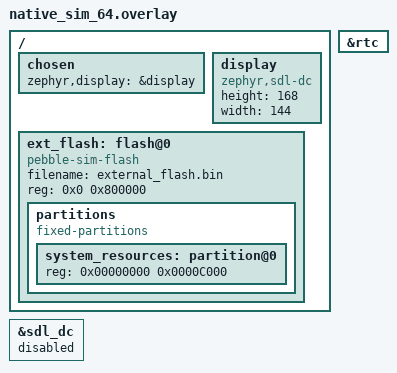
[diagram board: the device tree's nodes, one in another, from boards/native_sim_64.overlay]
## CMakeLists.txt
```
#-------------------------------------------------------------------------------
# PebbleOS CoreOS
#

cmake_minimum_required(VERSION 3.13.1)
find_package(Zephyr REQUIRED HINTS $ENV{ZEPHYR_BASE})

set(CMAKE_C_FLAGS "-Og")

project(CoreOS LANGUAGES C)

target_sources(app PRIVATE 
    src/main.c
)

add_subdirectory(src)
```

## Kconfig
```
# Copyright (c) 2021 Nordic Semiconductor ASA
# SPDX-License-Identifier: Apache-2.0
#
# This file is the application Kconfig entry point. All application Kconfig
# options can be defined here or included via other application Kconfig files.
# You can browse these options using the west targets menuconfig (terminal) or
# guiconfig (GUI).

menu "Zephyr"
    source "Kconfig.zephyr"

    choice
        prompt "Select target device"

        config DEVICE_TINTIN
            bool "Target TinTin Device"
        

        config DEVICE_BLANCA
            bool "Target Blanca Device"
    endchoice

endmenu

module = COREOS
module-str = COREOS

source "subsys/logging/Kconfig.template.log_config"
```

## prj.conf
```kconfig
# Display Configurations
CONFIG_DISPLAY=y

CONFIG_DEBUG_OPTIMIZATIONS=y

CONFIG_EVENTS=y

# RTC
#CONFIG_RTC=y
#CONFIG_RTC_UPDATE=y

# Flash
CONFIG_FLASH=y
CONFIG_FLASH_MAP=y

# CRC
CONFIG_CRC=y

# Logging
CONFIG_LOG=y
CONFIG_HEAP_MEM_POOL_SIZE=65536

# LVGL
CONFIG_LVGL=y
CONFIG_LV_CONF_MINIMAL=y
CONFIG_LV_USE_LOG=y
CONFIG_LV_LOG_LEVEL_TRACE=y
#CONFIG_LV_Z_FLUSH_THREAD=y
# CONFIG_LV_USE_LOG=y
CONFIG_LV_USE_LABEL=y
# CONFIG_LV_USE_ARC=y
# CONFIG_LV_USE_MONKEY=y
CONFIG_LV_COLOR_DEPTH_1=y
CONFIG_LV_Z_MEM_POOL_SIZE=16384
```

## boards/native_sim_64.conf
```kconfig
# Display Configs
CONFIG_SDL_DISPLAY=y
CONFIG_SDL_DISPLAY_DEFAULT_PIXEL_FORMAT_MONO10=y
CONFIG_SDL_DISPLAY_MONO_MSB_FIRST=n
CONFIG_SDL_DISPLAY_MONO_VTILED=n
CONFIG_SDL_DISPLAY_ZOOM_PCT=200

# Flash Sim
CONFIG_PEBBLE_SIM_FLASH=y
```

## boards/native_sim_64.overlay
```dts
/ {
    chosen {
        zephyr,display = &display;
    };

    display: display {
        compatible = "zephyr,sdl-dc";
        height = <168>;
        width = <144>;
    };

    ext_flash: flash@0 {
        compatible = "pebble-sim-flash";
        status = "okay";
        filename = "external_flash.bin";
        reg = < 0x0 0x800000 >;
		#address-cells = < 0x1 >;
		#size-cells = < 0x1 >;
	   
        partitions {
            compatible = "fixed-partitions";
            #address-cells = <1>;
            #size-cells = <1>;

            system_resources: partition@0 {
                reg = <0x00000000 0x0000C000>;
            };
        };

    };
};

&rtc {
    status = "okay";
};

&sdl_dc {
    status = "disabled";
};
```

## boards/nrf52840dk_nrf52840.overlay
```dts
/ {
	   
	
};

&mx25r64 {
	partitions {
  	compatible = "fixed-partitions";
    #address-cells = <1>;
    #size-cells = <1>;

    system_resources: partition@0 {
    	reg = <0x00000000 0x0000C000>;
    };
  };
};
```

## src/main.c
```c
/*
 * Copyright (C) Ovyl
 */

/**
 * @file main.c
 * @author Evan Stoddard
 * @brief
 */

#include <zephyr/kernel.h>

#include "kernel/main_thread.h"

#include "graphics/framebuffer.h"
#include "graphics/gcontext.h"
#include "ui/window.h"

#include "process_management/app_manager.h"

#include "apps/launcher/launcher_app.h"

#include "pebble_device.h"

/*****************************************************************************
 * Definitions
 *****************************************************************************/

/*****************************************************************************
 * Variables
 *****************************************************************************/

/*****************************************************************************
 * Private Functions
 *****************************************************************************/

Window window;

GContext context;
FrameBuffer fb;

/*****************************************************************************
 * Functions
 *****************************************************************************/

int main(void)
{

    GSize size = GSize(DEVICE_DISPLAY_WIDTH_PIXELS, DEVICE_DISPLAY_HEIGHT_PIXELS);

    framebuffer_init(&fb, &size);

    graphics_context_init(&context, &fb, GContextInitializationMode_App);

    /* launcher_app_main(); */

    /* window_render(launcher_app_window(), &context); */

    /* framebuffer_flush(&fb); */

    main_thread_init();

    static AppLaunchConfig launch_config = {0};
    launch_config.md = launcher_app_process_metadata();

    app_manager_start_app(&launch_config);

    return 0;
}
```

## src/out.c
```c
unsigned char outfile_bin[] = {
  0x00, 0x0c, 0x5d, 0x00, 0x00, 0x00, 0xff, 0x00, 0x00, 0x00, 0x00, 0x00,
  0x00, 0x00, 0x00, 0x00, 0x00, 0x00, 0x00, 0x00, 0x00, 0x00, 0x00, 0x00,
  0x00, 0x00, 0x00, 0x00, 0x00, 0x00, 0x00, 0x00, 0x00, 0x00, 0x00, 0x00,
  0x00, 0x00, 0x00, 0x00, 0x00, 0x00, 0x00, 0x00, 0x00, 0x00, 0x00, 0x00,
  0x00, 0x00, 0x00, 0x00, 0x00, 0x00, 0x00, 0x00, 0x00, 0x00, 0x00, 0x00,
  0x00, 0x00, 0x00, 0x00, 0x00, 0x00, 0x00, 0x00, 0x00, 0x00, 0x00, 0x00,
  0x00, 0x00, 0x00, 0x00, 0x00, 0x00, 0x00, 0x00, 0x00, 0x00, 0x00, 0x00,
  0x00, 0x00, 0x00, 0x00, 0x00, 0x00, 0x00, 0x00, 0x00, 0x00, 0x00, 0x00,
  0x00, 0x00, 0x00, 0x00, 0x00, 0x00, 0x00, 0x00, 0x00, 0x00, 0x00, 0x00,
  0x00, 0x00, 0x00, 0x00, 0x00, 0x00, 0x00, 0x00, 0x00, 0x00, 0x00, 0x00,
  0x00, 0x00, 0x00, 0x00, 0x00, 0x00, 0x00, 0x00, 0x00, 0x00, 0x00, 0x00,
  0x00, 0x00, 0x00, 0x00, 0x20, 0x01, 0x00, 0x00, 0x21, 0x01, 0x01, 0x00,
  0x22, 0x01, 0x02, 0x00, 0x23, 0x01, 0x03, 0x00, 0x24, 0x01, 0x04, 0x00,
  0x25, 0x01, 0x05, 0x00, 0x26, 0x01, 0x06, 0x00, 0x27, 0x01, 0x07, 0x00,
  0x28, 0x01, 0x08, 0x00, 0x29, 0x01, 0x09, 0x00, 0x2a, 0x01, 0x0a, 0x00,
  0x2b, 0x01, 0x0b, 0x00, 0x2c, 0x01, 0x0c, 0x00, 0x2d, 0x01, 0x0d, 0x00,
  0x2e, 0x01, 0x0e, 0x00, 0x2f, 0x01, 0x0f, 0x00, 0x30, 0x01, 0x10, 0x00,
  0x31, 0x01, 0x11, 0x00, 0x32, 0x01, 0x12, 0x00, 0x33, 0x01, 0x13, 0x00,
  0x34, 0x01, 0x14, 0x00, 0x35, 0x01, 0x15, 0x00, 0x36, 0x01, 0x16, 0x00,
  0x37, 0x01, 0x17, 0x00, 0x38, 0x01, 0x18, 0x00, 0x39, 0x01, 0x19, 0x00,
  0x3a, 0x01, 0x1a, 0x00, 0x3b, 0x01, 0x1b, 0x00, 0x3c, 0x01, 0x1c, 0x00,
  0x3d, 0x01, 0x1d, 0x00, 0x3e, 0x01, 0x1e, 0x00, 0x3f, 0x01, 0x1f, 0x00,
  0x40, 0x01, 0x20, 0x00, 0x41, 0x01, 0x21, 0x00, 0x42, 0x01, 0x22, 0x00,
  0x43, 0x01, 0x23, 0x00, 0x44, 0x01, 0x24, 0x00, 0x45, 0x01, 0x25, 0x00,
  0x46, 0x01, 0x26, 0x00, 0x47, 0x01, 0x27, 0x00, 0x48, 0x01, 0x28, 0x00,
  0x49, 0x01, 0x29, 0x00, 0x4a, 0x01, 0x2a, 0x00, 0x4b, 0x01, 0x2b, 0x00,
  0x4c, 0x01, 0x2c, 0x00, 0x4d, 0x01, 0x2d, 0x00, 0x4e, 0x01, 0x2e, 0x00,
  0x4f, 0x01, 0x2f, 0x00, 0x50, 0x01, 0x30, 0x00, 0x51, 0x01, 0x31, 0x00,
  0x52, 0x01, 0x32, 0x00, 0x53, 0x01, 0x33, 0x00, 0x54, 0x01, 0x34, 0x00,
  0x55, 0x01, 0x35, 0x00, 0x56, 0x01, 0x36, 0x00, 0x57, 0x01, 0x37, 0x00,
  0x58, 0x01, 0x38, 0x00, 0x59, 0x01, 0x39, 0x00, 0x5a, 0x01, 0x3a, 0x00,
  0x00, 0x00, 0x00, 0x00, 0x5c, 0x01, 0x3b, 0x00, 0x00, 0x00, 0x00, 0x00,
  0x5e, 0x01, 0x3c, 0x00, 0x5f, 0x01, 0x3d, 0x00, 0x60, 0x02, 0x3e, 0x00,
  0x61, 0x01, 0x40, 0x00, 0x62, 0x01, 0x41, 0x00, 0x63, 0x01, 0x42, 0x00,
  0x64, 0x01, 0x43, 0x00, 0x65, 0x01, 0x44, 0x00, 0x66, 0x01, 0x45, 0x00,
  0x67, 0x01, 0x46, 0x00, 0x68, 0x01, 0x47, 0x00, 0x69, 0x01, 0x48, 0x00,
  0x6a, 0x01, 0x49, 0x00, 0x6b, 0x01, 0x4a, 0x00, 0x6c, 0x01, 0x4b, 0x00,
  0x6d, 0x01, 0x4c, 0x00, 0x6e, 0x01, 0x4d, 0x00, 0x6f, 0x01, 0x4e, 0x00,
  0x70, 0x01, 0x4f, 0x00, 0x71, 0x01, 0x50, 0x00, 0x72, 0x01, 0x51, 0x00,
  0x73, 0x01, 0x52, 0x00, 0x74, 0x01, 0x53, 0x00, 0x75, 0x01, 0x54, 0x00,
  0x76, 0x01, 0x55, 0x00, 0x77, 0x01, 0x56, 0x00, 0x78, 0x01, 0x57, 0x00,
  0x79, 0x01, 0x58, 0x00, 0x7a, 0x01, 0x59, 0x00, 0x00, 0x00, 0x00, 0x00,
  0x7c, 0x01, 0x5a, 0x00, 0x00, 0x00, 0x00, 0x00, 0x7e, 0x02, 0x5b, 0x00,
  0x00, 0x00, 0x00, 0x00, 0x00, 0x00, 0x00, 0x00, 0x00, 0x00, 0x00, 0x00,
  0x00, 0x00, 0x00, 0x00, 0x00, 0x00, 0x00, 0x00, 0x00, 0x00, 0x00, 0x00,
  0x00, 0x00, 0x00, 0x00, 0x00, 0x00, 0x00, 0x00, 0x00, 0x00, 0x00, 0x00,
  0x00, 0x00, 0x00, 0x00, 0x00, 0x00, 0x00, 0x00, 0x00, 0x00, 0x00, 0x00,
  0x00, 0x00, 0x00, 0x00, 0x00, 0x00, 0x00, 0x00, 0x00, 0x00, 0x00, 0x00,
  0x00, 0x00, 0x00, 0x00, 0x00, 0x00, 0x00, 0x00, 0x00, 0x00, 0x00, 0x00,
  0x00, 0x00, 0x00, 0x00, 0x00, 0x00, 0x00, 0x00, 0x00, 0x00, 0x00, 0x00,
  0x00, 0x00, 0x00, 0x00, 0x00, 0x00, 0x00, 0x00, 0x00, 0x00, 0x00, 0x00,
  0x00, 0x00, 0x00, 0x00, 0x00, 0x00, 0x00, 0x00, 0x00, 0x00, 0x00, 0x00,
  0x00, 0x00, 0x00, 0x00, 0x00, 0x00, 0x00, 0x00, 0x00, 0x00, 0x00, 0x00,
  0x00, 0x00, 0x00, 0x00, 0x00, 0x00, 0x00, 0x00, 0x00, 0x00, 0x00, 0x00,
  0x00, 0x00, 0x00, 0x00, 0x00, 0x00, 0x00, 0x00, 0x00, 0x00, 0x00, 0x00,
  0x00, 0x00, 0x00, 0x00, 0x00, 0x00, 0x00, 0x00, 0x00, 0x00, 0x00, 0x00,
  0x00, 0x00, 0x00, 0x00, 0x00, 0x00, 0x00, 0x00, 0x00, 0x00, 0x00, 0x00,
  0x00, 0x00, 0x00, 0x00, 0x00, 0x00, 0x00, 0x00, 0x00, 0x00, 0x00, 0x00,
  0x00, 0x00, 0x00, 0x00, 0x00, 0x00, 0x00, 0x00, 0x00, 0x00, 0x00, 0x00,
  0x00, 0x00, 0x00, 0x00, 0x00, 0x00, 0x00, 0x00, 0x00, 0x00, 0x00, 0x00,
  0x00, 0x00, 0x00, 0x00, 0x00, 0x00, 0x00, 0x00, 0x00, 0x00, 0x00, 0x00,
  0x00, 0x00, 0x00, 0x00, 0x00, 0x00, 0x00, 0x00, 0x00, 0x00, 0x00, 0x00,
  0x00, 0x00, 0x00, 0x00, 0x00, 0x00, 0x00, 0x00, 0x00, 0x00, 0x00, 0x00,
  0x00, 0x00, 0x00, 0x00, 0x00, 0x00, 0x00, 0x00, 0x00, 0x00, 0x00, 0x00,
  0x00, 0x00, 0x00, 0x00, 0x00, 0x00, 0x00, 0x00, 0x00, 0x00, 0x00, 0x00,
  0x00, 0x00, 0x00, 0x00, 0x00, 0x00, 0x00, 0x00, 0x00, 0x00, 0x00, 0x00,
  0x00, 0x00, 0x00, 0x00, 0x00, 0x00, 0x00, 0x00, 0x00, 0x00, 0x00, 0x00,
  0x00, 0x00, 0x00, 0x00, 0x00, 0x00, 0x00, 0x00, 0x00, 0x00, 0x00, 0x00,
  0x00, 0x00, 0x00, 0x00, 0x00, 0x00, 0x00, 0x00, 0x00, 0x00, 0x00, 0x00,
  0x00, 0x00, 0x00, 0x00, 0x00, 0x00, 0x00, 0x00, 0x00, 0x00, 0x00, 0x00,
  0x00, 0x00, 0x00, 0x00, 0x00, 0x00, 0x00, 0x00, 0x00, 0x00, 0x00, 0x00,
  0x00, 0x00, 0x00, 0x00, 0x00, 0x00, 0x00, 0x00, 0x00, 0x00, 0x00, 0x00,
  0x00, 0x00, 0x00, 0x00, 0x00, 0x00, 0x00, 0x00, 0x00, 0x00, 0x00, 0x00,
  0x00, 0x00, 0x00, 0x00, 0x00, 0x00, 0x00, 0x00, 0x00, 0x00, 0x00, 0x00,
  0x00, 0x00, 0x00, 0x00, 0x00, 0x00, 0x00, 0x00, 0x00, 0x00, 0x00, 0x00,
  0x00, 0x00, 0x00, 0x00, 0x00, 0x00, 0x00, 0x00, 0x00, 0x00, 0x00, 0x00,
  0x00, 0x00, 0x00, 0x00, 0x00, 0x00, 0x00, 0x00, 0x00, 0x00, 0x00, 0x00,
  0x00, 0x00, 0x00, 0x00, 0x00, 0x00, 0x00, 0x00, 0x00, 0x00, 0x00, 0x00,
  0x00, 0x00, 0x00, 0x00, 0x00, 0x00, 0x00, 0x00, 0x00, 0x00, 0x00, 0x00,
  0x00, 0x00, 0x00, 0x00, 0x00, 0x00, 0x00, 0x00, 0x00, 0x00, 0x00, 0x00,
  0x00, 0x00, 0x00, 0x00, 0x00, 0x00, 0x00, 0x00, 0x00, 0x00, 0x00, 0x00,
  0x00, 0x00, 0x00, 0x00, 0x00, 0x00, 0x00, 0x00, 0x00, 0x00, 0x00, 0x00,
  0x00, 0x00, 0x00, 0x00, 0x00, 0x00, 0x00, 0x00, 0x00, 0x00, 0x00, 0x00,
  0x00, 0x00, 0x00, 0x00, 0x00, 0x00, 0x00, 0x00, 0x00, 0x00, 0x00, 0x00,
  0x00, 0x00, 0x00, 0x00, 0x00, 0x00, 0x00, 0x00, 0x00, 0x00, 0x00, 0x00,
  0x00, 0x00, 0x00, 0x00, 0x00, 0x00, 0x00, 0x00, 0x20, 0x00, 0x22, 0x02,
  0x21, 0x00, 0x83, 0x01, 0x22, 0x00, 0xeb, 0x01, 0x23, 0x00, 0x91, 0x01,
  0x24, 0x00, 0x97, 0x01, 0x25, 0x00, 0x9e, 0x01, 0x26, 0x00, 0xa9, 0x01,
  0x27, 0x00, 0xe7, 0x01, 0x28, 0x00, 0xb4, 0x01, 0x29, 0x00, 0xbc, 0x01,
  0x2a, 0x00, 0xaf, 0x01, 0x2b, 0x00, 0xca, 0x01, 0x2c, 0x00, 0xef, 0x01,
  0x2d, 0x00, 0xc4, 0x01, 0x2e, 0x00, 0xfd, 0x01, 0x2f, 0x00, 0x00, 0x02,
  0x30, 0x00, 0x47, 0x01, 0x31, 0x00, 0x4d, 0x01, 0x32, 0x00, 0x53, 0x01,
  0x33, 0x00, 0x59, 0x01, 0x34, 0x00, 0x5f, 0x01, 0x35, 0x00, 0x65, 0x01,
  0x36, 0x00, 0x6b, 0x01, 0x37, 0x00, 0x71, 0x01, 0x38, 0x00, 0x77, 0x01,
  0x39, 0x00, 0x7d, 0x01, 0x3a, 0x00, 0xe1, 0x01, 0x3b, 0x00, 0xda, 0x01,
  0x3c, 0x00, 0xf3, 0x01, 0x3d, 0x00, 0xd0, 0x01, 0x3e, 0x00, 0xf8, 0x01,
  0x3f, 0x00, 0x07, 0x02, 0x40, 0x00, 0x89, 0x01, 0x41, 0x00, 0xaa, 0x00,
  0x42, 0x00, 0xb0, 0x00, 0x43, 0x00, 0xb6, 0x00, 0x44, 0x00, 0xbc, 0x00,
  0x45, 0x00, 0xc2, 0x00, 0x46, 0x00, 0xc8, 0x00, 0x47, 0x00, 0xce, 0x00,
  0x48, 0x00, 0xd4, 0x00, 0x49, 0x00, 0xda, 0x00, 0x4a, 0x00, 0xe0, 0x00,
  0x4b, 0x00, 0xe6, 0x00, 0x4c, 0x00, 0xec, 0x00, 0x4d, 0x00, 0xf2, 0x00,
  0x4e, 0x00, 0xf8, 0x00, 0x4f, 0x00, 0xfe, 0x00, 0x50, 0x00, 0x04, 0x01,
  0x51, 0x00, 0x0a, 0x01, 0x52, 0x00, 0x11, 0x01, 0x53, 0x00, 0x17, 0x01,
  0x54, 0x00, 0x1d, 0x01, 0x55, 0x00, 0x23, 0x01, 0x56, 0x00, 0x29, 0x01,
  0x57, 0x00, 0x2f, 0x01, 0x58, 0x00, 0x35, 0x01, 0x59, 0x00, 0x3b, 0x01,
  0x5a, 0x00, 0x41, 0x01, 0x5c, 0x00, 0x0d, 0x02, 0x5e, 0x00, 0xa4, 0x01,
  0x5f, 0x00, 0xc7, 0x01, 0x60, 0x00, 0xd7, 0x01, 0x60, 0x00, 0x1c, 0x02,
  0x61, 0x00, 0x00, 0x00, 0x62, 0x00, 0x06, 0x00, 0x63, 0x00, 0x0d, 0x00,
  0x64, 0x00, 0x13, 0x00, 0x65, 0x00, 0x1a, 0x00, 0x66, 0x00, 0x20, 0x00,
  0x67, 0x00, 0x27, 0x00, 0x68, 0x00, 0x2e, 0x00, 0x69, 0x00, 0x35, 0x00,
  0x6a, 0x00, 0x3c, 0x00, 0x6b, 0x00, 0x44, 0x00, 0x6c, 0x00, 0x4b, 0x00,
  0x6d, 0x00, 0x52, 0x00, 0x6e, 0x00, 0x58, 0x00, 0x6f, 0x00, 0x5e, 0x00,
  0x70, 0x00, 0x64, 0x00, 0x71, 0x00, 0x6b, 0x00, 0x72, 0x00, 0x72, 0x00,
  0x73, 0x00, 0x78, 0x00, 0x74, 0x00, 0x7e, 0x00, 0x75, 0x00, 0x85, 0x00,
  0x76, 0x00, 0x8b, 0x00, 0x77, 0x00, 0x91, 0x00, 0x78, 0x00, 0x97, 0x00,
  0x79, 0x00, 0x9d, 0x00, 0x7a, 0x00, 0xa4, 0x00, 0x7c, 0x00, 0x14, 0x02,
  0x7e, 0x00, 0xd4, 0x01, 0x7e, 0x00, 0x1f, 0x02, 0x06, 0x07, 0x05, 0x01,
  0x00, 0x00, 0x00, 0x07, 0x70, 0x00, 0x98, 0x00, 0x08, 0x00, 0xf8, 0x00,
  0x88, 0x00, 0x98, 0x00, 0xec, 0x00, 0x00, 0x00, 0x05, 0x09, 0x03, 0x01,
  0x00, 0x00, 0x00, 0x07, 0x80, 0x00, 0x80, 0x00, 0xb0, 0x00, 0xc8, 0x00,
  0x88, 0x00, 0x88, 0x00, 0x88, 0x00, 0xc8, 0x00, 0xb0, 0x00, 0x00, 0x00,
  0x05, 0x07, 0x05, 0x01, 0x00, 0x00, 0x00, 0x07, 0x70, 0x00, 0x88, 0x00,
  0x80, 0x00, 0x80, 0x00, 0x80, 0x00, 0x88, 0x00, 0x70, 0x00, 0x00, 0x00,
  0x05, 0x09, 0x03, 0x01, 0x00, 0x00, 0x00, 0x07, 0x08, 0x00, 0x08, 0x00,
  0x68, 0x00, 0x98, 0x00, 0x88, 0x00, 0x88, 0x00, 0x88, 0x00, 0x98, 0x00,
  0x68, 0x00, 0x00, 0x00, 0x05, 0x07, 0x05, 0x01, 0x00, 0x00, 0x00, 0x07,
  0x70, 0x00, 0x88, 0x00, 0x88, 0x00, 0xf8, 0x00, 0x80, 0x00, 0x88, 0x00,
  0x70, 0x00, 0x00, 0x00, 0x05, 0x09, 0x03, 0x01, 0x00, 0x00, 0x00, 0x07,
  0x38, 0x00, 0x40, 0x00, 0xf8, 0x00, 0x40, 0x00, 0x40, 0x00, 0x40, 0x00,
  0x40, 0x00, 0x40, 0x00, 0x40, 0x00, 0x00, 0x00, 0x05, 0x09, 0x05, 0x01,
  0x00, 0x00, 0x00, 0x07, 0x68, 0x00, 0x98, 0x00, 0x88, 0x00, 0x88, 0x00,
  0x88, 0x00, 0x98, 0x00, 0x68, 0x00, 0x08, 0x00, 0x70, 0x00, 0x00, 0x00,
  0x05, 0x09, 0x03, 0x01, 0x00, 0x00, 0x00, 0x07, 0x80, 0x00, 0x80, 0x00,
  0xb0, 0x00, 0xc8, 0x00, 0x88, 0x00, 0x88, 0x00, 0x88, 0x00, 0x88, 0x00,
  0x88, 0x00, 0x00, 0x00, 0x06, 0x09, 0x03, 0x01, 0x00, 0x00, 0x00, 0x07,
  0x20, 0x00, 0x00, 0x00, 0xe0, 0x00, 0x20, 0x00, 0x20, 0x00, 0x20, 0x00,
  0x20, 0x00, 0x20, 0x00, 0xfc, 0x00, 0x00, 0x00, 0x04, 0x0b, 0x03, 0x01,
  0x00, 0x00, 0x00, 0x07, 0x10, 0x00, 0x00, 0x00, 0xf0, 0x00, 0x10, 0x00,
  0x10, 0x00, 0x10, 0x00, 0x10, 0x00, 0x10, 0x00, 0x10, 0x00, 0x30, 0x00,
  0xe0, 0x00, 0x00, 0x00, 0x05, 0x09, 0x03, 0x01, 0x00, 0x00, 0x00, 0x07,
  0x80, 0x00, 0x80, 0x00, 0x88, 0x00, 0x90, 0x00, 0xa0, 0x00, 0xe0, 0x00,
  0x90, 0x00, 0x90, 0x00, 0x88, 0x00, 0x00, 0x00, 0x05, 0x09, 0x03, 0x02,
  0x00, 0x00, 0x00, 0x07, 0xc0, 0x00, 0x40, 0x00, 0x40, 0x00, 0x40, 0x00,
  0x40, 0x00, 0x40, 0x00, 0x40, 0x00, 0x40, 0x00, 0x78, 0x00, 0x00, 0x00,
  0x05, 0x07, 0x05, 0x01, 0x00, 0x00, 0x00, 0x07, 0xf8, 0x00, 0xa8, 0x00,
  0xa8, 0x00, 0xa8, 0x00, 0xa8, 0x00, 0xa8, 0x00, 0xa8, 0x00, 0x00, 0x00,
  0x05, 0x07, 0x05, 0x01, 0x00, 0x00, 0x00, 0x07, 0xb0, 0x00, 0xc8, 0x00,
  0x88, 0x00, 0x88, 0x00, 0x88, 0x00, 0x88, 0x00, 0x88, 0x00, 0x00, 0x00,
  0x05, 0x07, 0x05, 0x01, 0x00, 0x00, 0x00, 0x07, 0x70, 0x00, 0x88, 0x00,
  0x88, 0x00, 0x88, 0x00, 0x88, 0x00, 0x88, 0x00, 0x70, 0x00, 0x00, 0x00,
  0x05, 0x09, 0x05, 0x01, 0x00, 0x00, 0x00, 0x07, 0xb0, 0x00, 0xc8, 0x00,
  0x88, 0x00, 0x88, 0x00, 0x88, 0x00, 0xc8, 0x00, 0xb0, 0x00, 0x80, 0x00,
  0x80, 0x00, 0x00, 0x00, 0x05, 0x09, 0x05, 0x01, 0x00, 0x00, 0x00, 0x07,
  0x68, 0x00, 0x98, 0x00, 0x88, 0x00, 0x88, 0x00, 0x88, 0x00, 0x98, 0x00,
  0x68, 0x00, 0x08, 0x00, 0x08, 0x00, 0x00, 0x00, 0x05, 0x07, 0x05, 0x01,
  0x00, 0x00, 0x00, 0x07, 0xb8, 0x00, 0x60, 0x00, 0x40, 0x00, 0x40, 0x00,
  0x40, 0x00, 0x40, 0x00, 0x40, 0x00, 0x00, 0x00, 0x05, 0x07, 0x05, 0x01,
  0x00, 0x00, 0x00, 0x07, 0x70, 0x00, 0x88, 0x00, 0xc0, 0x00, 0x70, 0x00,
  0x08, 0x00, 0x88, 0x00, 0x70, 0x00, 0x00, 0x00, 0x05, 0x09, 0x03, 0x01,
  0x00, 0x00, 0x00, 0x07, 0x40, 0x00, 0x40, 0x00, 0xf8, 0x00, 0x40, 0x00,
  0x40, 0x00, 0x40, 0x00, 0x40, 0x00, 0x40, 0x00, 0x78, 0x00, 0x00, 0x00,
  0x05, 0x07, 0x05, 0x01, 0x00, 0x00, 0x00, 0x07, 0x88, 0x00, 0x88, 0x00,
  0x88, 0x00, 0x88, 0x00, 0x88, 0x00, 0x98, 0x00, 0x68, 0x00, 0x00, 0x00,
  0x07, 0x07, 0x05, 0x00, 0x00, 0x00, 0x00, 0x07, 0x44, 0x00, 0x44, 0x00,
  0x44, 0x00, 0x28, 0x00, 0x28, 0x00, 0x28, 0x00, 0x10, 0x00, 0x00, 0x00,
  0x07, 0x07, 0x05, 0x00, 0x00, 0x00, 0x00, 0x07, 0x82, 0x00, 0x82, 0x00,
  0x94, 0x00, 0x6c, 0x00, 0x6c, 0x00, 0x6c, 0x00, 0x4c, 0x00, 0x00, 0x00,
  0x05, 0x07, 0x05, 0x01, 0x00, 0x00, 0x00, 0x07, 0x88, 0x00, 0x50, 0x00,
  0x50, 0x00, 0x20, 0x00, 0x50, 0x00, 0x50, 0x00, 0x88, 0x00, 0x00, 0x00,
  0x07, 0x09, 0x05, 0x00, 0x00, 0x00, 0x00, 0x07, 0x44, 0x00, 0x44, 0x00,
  0x64, 0x00, 0x28, 0x00, 0x28, 0x00, 0x10, 0x00, 0x10, 0x00, 0x30, 0x00,
  0x60, 0x00, 0x00, 0x00, 0x05, 0x07, 0x05, 0x01, 0x00, 0x00, 0x00, 0x07,
  0xf8, 0x00, 0x10, 0x00, 0x10, 0x00, 0x20, 0x00, 0x40, 0x00, 0x80, 0x00,
  0xf8, 0x00, 0x00, 0x00, 0x07, 0x08, 0x04, 0x00, 0x00, 0x00, 0x00, 0x07,
  0x10, 0x00, 0x28, 0x00, 0x28, 0x00, 0x28, 0x00, 0x44, 0x00, 0x7c, 0x00,
  0x44, 0x00, 0x82, 0x00, 0x06, 0x08, 0x04, 0x01, 0x00, 0x00, 0x00, 0x07,
  0xf0, 0x00, 0x88, 0x00, 0x88, 0x00, 0xf0, 0x00, 0x88, 0x00, 0x8c, 0x00,
  0x88, 0x00, 0xf8, 0x00, 0x06, 0x08, 0x04, 0x01, 0x00, 0x00, 0x00, 0x07,
  0x70, 0x00, 0x88, 0x00, 0x80, 0x00, 0x80, 0x00, 0x80, 0x00, 0x80, 0x00,
  0xc8, 0x00, 0x78, 0x00, 0x05, 0x08, 0x04, 0x01, 0x00, 0x00, 0x00, 0x07,
  0xf0, 0x00, 0x98, 0x00, 0x88, 0x00, 0x88, 0x00, 0x88, 0x00, 0x88, 0x00,
  0x98, 0x00, 0xf0, 0x00, 0x05, 0x08, 0x04, 0x01, 0x00, 0x00, 0x00, 0x07,
  0xf8, 0x00, 0x80, 0x00, 0x80, 0x00, 0xf8, 0x00, 0x80, 0x00, 0x80, 0x00,
  0x80, 0x00, 0xf8, 0x00, 0x05, 0x08, 0x04, 0x01, 0x00, 0x00, 0x00, 0x07,
  0xf8, 0x00, 0x80, 0x00, 0x80, 0x00, 0xf8, 0x00, 0x80, 0x00, 0x80, 0x00,
  0x80, 0x00, 0x80, 0x00, 0x05, 0x08, 0x04, 0x01, 0x00, 0x00, 0x00, 0x07,
  0x70, 0x00, 0x88, 0x00, 0x80, 0x00, 0x80, 0x00, 0x98, 0x00, 0x88, 0x00,
  0x88, 0x00, 0x78, 0x00, 0x05, 0x08, 0x04, 0x01, 0x00, 0x00, 0x00, 0x07,
  0x88, 0x00, 0x88, 0x00, 0x88, 0x00, 0xf8, 0x00, 0x88, 0x00, 0x88, 0x00,
  0x88, 0x00, 0x88, 0x00, 0x05, 0x08, 0x04, 0x01, 0x00, 0x00, 0x00, 0x07,
  0xf8, 0x00, 0x20, 0x00, 0x20, 0x00, 0x20, 0x00, 0x20, 0x00, 0x20, 0x00,
  0x20, 0x00, 0xf8, 0x00, 0x05, 0x08, 0x04, 0x01, 0x00, 0x00, 0x00, 0x07,
  0x38, 0x00, 0x18, 0x00, 0x18, 0x00, 0x18, 0x00, 0x18, 0x00, 0x18, 0x00,
  0x90, 0x00, 0x70, 0x00, 0x06, 0x08, 0x04, 0x01, 0x00, 0x00, 0x00, 0x07,
  0x88, 0x00, 0x90, 0x00, 0xa0, 0x00, 0xe0, 0x00, 0xa0, 0x00, 0x90, 0x00,
  0x88, 0x00, 0x8c, 0x00, 0x05, 0x08, 0x04, 0x01, 0x00, 0x00, 0x00, 0x07,
  0x80, 0x00, 0x80, 0x00, 0x80, 0x00, 0x80, 0x00, 0x80, 0x00, 0x80, 0x00,
  0x80, 0x00, 0xf8, 0x00, 0x05, 0x08, 0x04, 0x01, 0x00, 0x00, 0x00, 0x07,
  0x88, 0x00, 0xd8, 0x00, 0xd8, 0x00, 0xd8, 0x00, 0xa8, 0x00, 0x88, 0x00,
  0x88, 0x00, 0x88, 0x00, 0x05, 0x08, 0x04, 0x01, 0x00, 0x00, 0x00, 0x07,
  0x88, 0x00, 0xc8, 0x00, 0xc8, 0x00, 0xa8, 0x00, 0xa8, 0x00, 0x98, 0x00,
  0x98, 0x00, 0x88, 0x00, 0x05, 0x08, 0x04, 0x01, 0x00, 0x00, 0x00, 0x07,
  0x70, 0x00, 0x88, 0x00, 0x88, 0x00, 0x88, 0x00, 0x88, 0x00, 0x88, 0x00,
  0x88, 0x00, 0x70, 0x00, 0x05, 0x08, 0x04, 0x01, 0x00, 0x00, 0x00, 0x07,
  0xf0, 0x00, 0x88, 0x00, 0x88, 0x00, 0x88, 0x00, 0xf0, 0x00, 0x80, 0x00,
  0x80, 0x00, 0x80, 0x00, 0x05, 0x0a, 0x04, 0x01, 0x00, 0x00, 0x00, 0x07,
  0x70, 0x00, 0x88, 0x00, 0x88, 0x00, 0x88, 0x00, 0x88, 0x00, 0x88, 0x00,
  0x88, 0x00, 0x70, 0x00, 0x30, 0x00, 0x18, 0x00, 0x06, 0x08, 0x04, 0x01,
  0x00, 0x00, 0x00, 0x07, 0xf8, 0x00, 0x88, 0x00, 0x88, 0x00, 0xf0, 0x00,
  0x90, 0x00, 0x90, 0x00, 0x88, 0x00, 0x88, 0x00, 0x06, 0x08, 0x04, 0x00,
  0x00, 0x00, 0x00, 0x07, 0x38, 0x00, 0x44, 0x00, 0x40, 0x00, 0x70, 0x00,
  0x0c, 0x00, 0x04, 0x00, 0x44, 0x00, 0x7c, 0x00, 0x07, 0x08, 0x04, 0x00,
  0x00, 0x00, 0x00, 0x07, 0xfe, 0x00, 0x10, 0x00, 0x10, 0x00, 0x10, 0x00,
  0x10, 0x00, 0x10, 0x00, 0x10, 0x00, 0x10, 0x00, 0x05, 0x08, 0x04, 0x01,
  0x00, 0x00, 0x00, 0x07, 0x88, 0x00, 0x88, 0x00, 0x88, 0x00, 0x88, 0x00,
  0x88, 0x00, 0x88, 0x00, 0x88, 0x00, 0x70, 0x00, 0x07, 0x08, 0x04, 0x00,
  0x00, 0x00, 0x00, 0x07, 0x82, 0x00, 0x44, 0x00, 0x44, 0x00, 0x44, 0x00,
  0x28, 0x00, 0x28, 0x00, 0x28, 0x00, 0x10, 0x00, 0x07, 0x08, 0x04, 0x00,
  0x00, 0x00, 0x00, 0x07, 0x82, 0x00, 0x82, 0x00, 0x92, 0x00, 0x54, 0x00,
  0x6c, 0x00, 0x6c, 0x00, 0x6c, 0x00, 0x6c, 0x00, 0x07, 0x08, 0x04, 0x00,
  0x00, 0x00, 0x00, 0x07, 0x44, 0x00, 0x6c, 0x00, 0x28, 0x00, 0x10, 0x00,
  0x38, 0x00, 0x28, 0x00, 0x44, 0x00, 0x44, 0x00, 0x07, 0x08, 0x04, 0x00,
  0x00, 0x00, 0x00, 0x07, 0xc6, 0x00, 0x44, 0x00, 0x28, 0x00, 0x10, 0x00,
  0x10, 0x00, 0x10, 0x00, 0x10, 0x00, 0x10, 0x00, 0x07, 0x08, 0x04, 0x00,
  0x00, 0x00, 0x00, 0x07, 0x7c, 0x00, 0x04, 0x00, 0x08, 0x00, 0x10, 0x00,
  0x30, 0x00, 0x20, 0x00, 0x40, 0x00, 0xfe, 0x00, 0x05, 0x08, 0x04, 0x01,
  0x00, 0x00, 0x00, 0x07, 0x70, 0x00, 0x88, 0x00, 0x88, 0x00, 0xa8, 0x00,
  0x88, 0x00, 0x88, 0x00, 0x88, 0x00, 0x70, 0x00, 0x06, 0x08, 0x04, 0x01,
  0x00, 0x00, 0x00, 0x07, 0x20, 0x00, 0xe0, 0x00, 0x20, 0x00, 0x20, 0x00,
  0x20, 0x00, 0x20, 0x00, 0x20, 0x00, 0xfc, 0x00, 0x05, 0x08, 0x04, 0x01,
  0x00, 0x00, 0x00, 0x07, 0x70, 0x00, 0x88, 0x00, 0x08, 0x00, 0x18, 0x00,
  0x30, 0x00, 0x40, 0x00, 0x80, 0x00, 0xf8, 0x00, 0x05, 0x08, 0x04, 0x01,
  0x00, 0x00, 0x00, 0x07, 0x70, 0x00, 0x88, 0x00, 0x08, 0x00, 0x30, 0x00,
  0x08, 0x00, 0x08, 0x00, 0x88, 0x00, 0x70, 0x00, 0x05, 0x08, 0x04, 0x01,
  0x00, 0x00, 0x00, 0x07, 0x10, 0x00, 0x30, 0x00, 0x50, 0x00, 0x50, 0x00,
  0x90, 0x00, 0xf8, 0x00, 0x10, 0x00, 0x10, 0x00, 0x05, 0x08, 0x04, 0x01,
  0x00, 0x00, 0x00, 0x07, 0xf8, 0x00, 0x80, 0x00, 0x80, 0x00, 0xf0, 0x00,
  0x08, 0x00, 0x08, 0x00, 0x88, 0x00, 0x70, 0x00, 0x05, 0x08, 0x04, 0x01,
  0x00, 0x00, 0x00, 0x07, 0x70, 0x00, 0xc8, 0x00, 0x80, 0x00, 0xf0, 0x00,
  0x88, 0x00, 0x88, 0x00, 0x88, 0x00, 0x70, 0x00, 0x05, 0x08, 0x04, 0x01,
  0x00, 0x00, 0x00, 0x07, 0xf8, 0x00, 0x08, 0x00, 0x10, 0x00, 0x10, 0x00,
  0x20, 0x00, 0x20, 0x00, 0x60, 0x00, 0x40, 0x00, 0x05, 0x08, 0x04, 0x01,
  0x00, 0x00, 0x00, 0x07, 0x70, 0x00, 0x88, 0x00, 0x88, 0x00, 0x70, 0x00,
  0x88, 0x00, 0x88, 0x00, 0x88, 0x00, 0x70, 0x00, 0x05, 0x08, 0x04, 0x01,
  0x00, 0x00, 0x00, 0x07, 0x70, 0x00, 0x88, 0x00, 0x88, 0x00, 0x88, 0x00,
  0x78, 0x00, 0x08, 0x00, 0x98, 0x00, 0x70, 0x00, 0x01, 0x08, 0x04, 0x03,
  0x00, 0x00, 0x00, 0x07, 0x80, 0x00, 0x80, 0x00, 0x80, 0x00, 0x80, 0x00,
  0x80, 0x00, 0x80, 0x00, 0x00, 0x00, 0x80, 0x00, 0x07, 0x0b, 0x03, 0x00,
  0x00, 0x00, 0x00, 0x07, 0x38, 0x00, 0x44, 0x00, 0x42, 0x00, 0x9e, 0x00,
  0xaa, 0x00, 0xaa, 0x00, 0xaa, 0x00, 0xbc, 0x00, 0x80, 0x00, 0x44, 0x00,
  0x38, 0x00, 0x00, 0x00, 0x07, 0x08, 0x04, 0x00, 0x00, 0x00, 0x00, 0x07,
  0x24, 0x00, 0x24, 0x00, 0x7e, 0x00, 0x28, 0x00, 0x48, 0x00, 0xfc, 0x00,
  0x48, 0x00, 0x48, 0x00, 0x07, 0x0a, 0x03, 0x00, 0x00, 0x00, 0x00, 0x07,
  0x10, 0x00, 0x7c, 0x00, 0x54, 0x00, 0x50, 0x00, 0x38, 0x00, 0x14, 0x00,
  0x12, 0x00, 0xd4, 0x00, 0x7c, 0x00, 0x10, 0x00, 0x07, 0x08, 0x04, 0x00,
  0x00, 0x00, 0x00, 0x07, 0xe4, 0x00, 0xa4, 0x00, 0xa8, 0x00, 0xf0, 0x00,
  0x1e, 0x00, 0x2a, 0x00, 0x4a, 0x00, 0x4e, 0x00, 0x05, 0x05, 0x04, 0x01,
  0x00, 0x00, 0x00, 0x07, 0x20, 0x00, 0x50, 0x00, 0x50, 0x00, 0x88, 0x00,
  0x88, 0x00, 0x00, 0x00, 0x07, 0x08, 0x04, 0x00, 0x00, 0x00, 0x00, 0x07,
  0x38, 0x00, 0x48, 0x00, 0x48, 0x00, 0x30, 0x00, 0x64, 0x00, 0x94, 0x00,
  0xc8, 0x00, 0x76, 0x00, 0x05, 0x05, 0x03, 0x01, 0x00, 0x00, 0x00, 0x07,
  0x20, 0x00, 0xf0, 0x00, 0x20, 0x00, 0x50, 0x00, 0x50, 0x00, 0x00, 0x00,
  0x03, 0x0b, 0x03, 0x02, 0x00, 0x00, 0x00, 0x07, 0x20, 0x00, 0x40, 0x00,
  0xc0, 0x00, 0x80, 0x00, 0x80, 0x00, 0x80, 0x00, 0x80, 0x00, 0x80, 0x00,
  0xc0, 0x00, 0x40, 0x00, 0x20, 0x00, 0x00, 0x00, 0x03, 0x0b, 0x03, 0x02,
  0x00, 0x00, 0x00, 0x07, 0x80, 0x00, 0x40, 0x00, 0x60, 0x00, 0x20, 0x00,
  0x20, 0x00, 0x20, 0x00, 0x20, 0x00, 0x20, 0x00, 0x60, 0x00, 0x40, 0x00,
  0x80, 0x00, 0x00, 0x00, 0x03, 0x01, 0x08, 0x02, 0x00, 0x00, 0x00, 0x07,
  0xe0, 0x00, 0x00, 0x00, 0x07, 0x01, 0x0d, 0x00, 0x00, 0x00, 0x00, 0x07,
  0xfe, 0x00, 0x00, 0x00, 0x05, 0x07, 0x04, 0x01, 0x00, 0x00, 0x00, 0x07,
  0x20, 0x00, 0x20, 0x00, 0x20, 0x00, 0xf8, 0x00, 0x20, 0x00, 0x20, 0x00,
  0x20, 0x00, 0x00, 0x00, 0x05, 0x04, 0x06, 0x01, 0x00, 0x00, 0x00, 0x07,
  0xf8, 0x00, 0x00, 0x00, 0x00, 0x00, 0xf8, 0x00, 0x05, 0x02, 0x07, 0x01,
  0x00, 0x00, 0x00, 0x07, 0xe0, 0x00, 0x38, 0x00, 0x03, 0x02, 0x02, 0x02,
  0x00, 0x00, 0x00, 0x07, 0x40, 0x00, 0x20, 0x00, 0x02, 0x09, 0x05, 0x02,
  0x00, 0x00, 0x00, 0x07, 0x40, 0x00, 0x40, 0x00, 0x00, 0x00, 0x00, 0x00,
  0x00, 0x00, 0x40, 0x00, 0x40, 0x00, 0x80, 0x00, 0x80, 0x00, 0x00, 0x00,
  0x01, 0x07, 0x05, 0x03, 0x00, 0x00, 0x00, 0x07, 0x80, 0x00, 0x80, 0x00,
  0x00, 0x00, 0x00, 0x00, 0x00, 0x00, 0x80, 0x00, 0x80, 0x00, 0x00, 0x00,
  0x01, 0x04, 0x03, 0x03, 0x00, 0x00, 0x00, 0x07, 0x80, 0x00, 0x80, 0x00,
  0x80, 0x00, 0x80, 0x00, 0x03, 0x04, 0x03, 0x02, 0x00, 0x00, 0x00, 0x07,
  0xa0, 0x00, 0xa0, 0x00, 0xa0, 0x00, 0xa0, 0x00, 0x03, 0x04, 0x0a, 0x01,
  0x00, 0x00, 0x00, 0x07, 0x60, 0x00, 0x40, 0x00, 0x40, 0x00, 0x80, 0x00,
  0x05, 0x05, 0x05, 0x01, 0x00, 0x00, 0x00, 0x07, 0x08, 0x00, 0x70, 0x00,
  0x80, 0x00, 0x70, 0x00, 0x08, 0x00, 0x00, 0x00, 0x05, 0x05, 0x05, 0x01,
  0x00, 0x00, 0x00, 0x07, 0x80, 0x00, 0x70, 0x00, 0x08, 0x00, 0x70, 0x00,
  0x80, 0x00, 0x00, 0x00, 0x01, 0x02, 0x0a, 0x03, 0x00, 0x00, 0x00, 0x07,
  0x80, 0x00, 0x80, 0x00, 0x05, 0x09, 0x03, 0x01, 0x00, 0x00, 0x00, 0x07,
  0x08, 0x00, 0x08, 0x00, 0x10, 0x00, 0x10, 0x00, 0x20, 0x00, 0x60, 0x00,
  0x40, 0x00, 0x80, 0x00, 0x80, 0x00, 0x00, 0x00, 0x05, 0x08, 0x04, 0x01,
  0x00, 0x00, 0x00, 0x07, 0xf0, 0x00, 0x88, 0x00, 0x08, 0x00, 0x18, 0x00,
  0x30, 0x00, 0x20, 0x00, 0x00, 0x00, 0x20, 0x00, 0x05, 0x09, 0x03, 0x01,
  0x00, 0x00, 0x00, 0x07, 0x80, 0x00, 0x80, 0x00, 0x40, 0x00, 0x60, 0x00,
  0x20, 0x00, 0x30, 0x00, 0x10, 0x00, 0x08, 0x00, 0x08, 0x00, 0x00, 0x00,
  0x01, 0x0b, 0x03, 0x03, 0x00, 0x00, 0x00, 0x07, 0x80, 0x00, 0x80, 0x00,
  0x80, 0x00, 0x80, 0x00, 0x80, 0x00, 0x80, 0x00, 0x80, 0x00, 0x80, 0x00,
  0x80, 0x00, 0x80, 0x00, 0x80, 0x00, 0x00, 0x00, 0x03, 0x02, 0x02, 0x02,
  0x00, 0x00, 0x00, 0x07, 0x40, 0x00, 0x20, 0x00, 0x05, 0x02, 0x07, 0x01,
  0x00, 0x00, 0x00, 0x07, 0xe0, 0x00, 0x38, 0x00, 0x01, 0x01, 0x0b, 0x00,
  0x00, 0x00, 0x00, 0x07, 0x00, 0x00, 0x00, 0x00
};
unsigned int outfile_bin_len = 3596;
```
